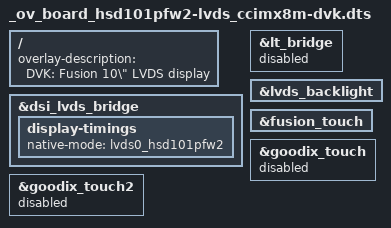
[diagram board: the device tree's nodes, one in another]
/*
 * Copyright 2020-2021 Digi International Inc.
 *
 * Permission to use, copy, modify, and/or distribute this software for any
 * purpose with or without fee is hereby granted, provided that the above
 * copyright notice and this permission notice appear in all copies.
 * THE SOFTWARE IS PROVIDED "AS IS" AND THE AUTHOR DISCLAIMS ALL WARRANTIES
 * WITH REGARD TO THIS SOFTWARE INCLUDING ALL IMPLIED WARRANTIES OF
 * MERCHANTABILITY AND FITNESS. IN NO EVENT SHALL THE AUTHOR BE LIABLE FOR
 * ANY SPECIAL, DIRECT, INDIRECT, OR CONSEQUENTIAL DAMAGES OR ANY DAMAGES
 * WHATSOEVER RESULTING FROM LOSS OF USE, DATA OR PROFITS, WHETHER IN AN
 * ACTION OF CONTRACT, NEGLIGENCE OR OTHER TORTIOUS ACTION, ARISING OUT OF
 * OR IN CONNECTION WITH THE USE OR PERFORMANCE OF THIS SOFTWARE.
 */

/dts-v1/;
/plugin/;

/ {
	fragment@0 {
		target-path = "/";
		__overlay__ {
			overlay-description = "DVK: Fusion 10\" LVDS display";
		};
	};

	/* Enable the LVDS bridge and target the Fusion 10" display */
	fragment@1 {
		target = <&dsi_lvds_bridge>;
		__overlay__ {
			status = "okay";
			display-timings {
				native-mode = <&lvds0_hsd101pfw2>;
			};
		};
	};

	/* Disable the HDMI bridge */
	fragment@2 {
		target = <&lt_bridge>;
		__overlay__ {
			status = "disabled";
		};
	};

	/* Enable lvds_backlight */
	fragment@3 {
		target = <&lvds_backlight>;
		__overlay__ {
			status = "okay";
		};
	};

	/* Enable Fusion touch */
	fragment@4 {
		target = <&fusion_touch>;
		__overlay__ {
			status = "okay";
		};
	};

	/* Disable Goodix touch */
	fragment@5 {
		target = <&goodix_touch>;
		__overlay__ {
			status = "disabled";
		};
	};

	fragment@6 {
		target = <&goodix_touch2>;
		__overlay__ {
			status = "disabled";
		};
	};
};
